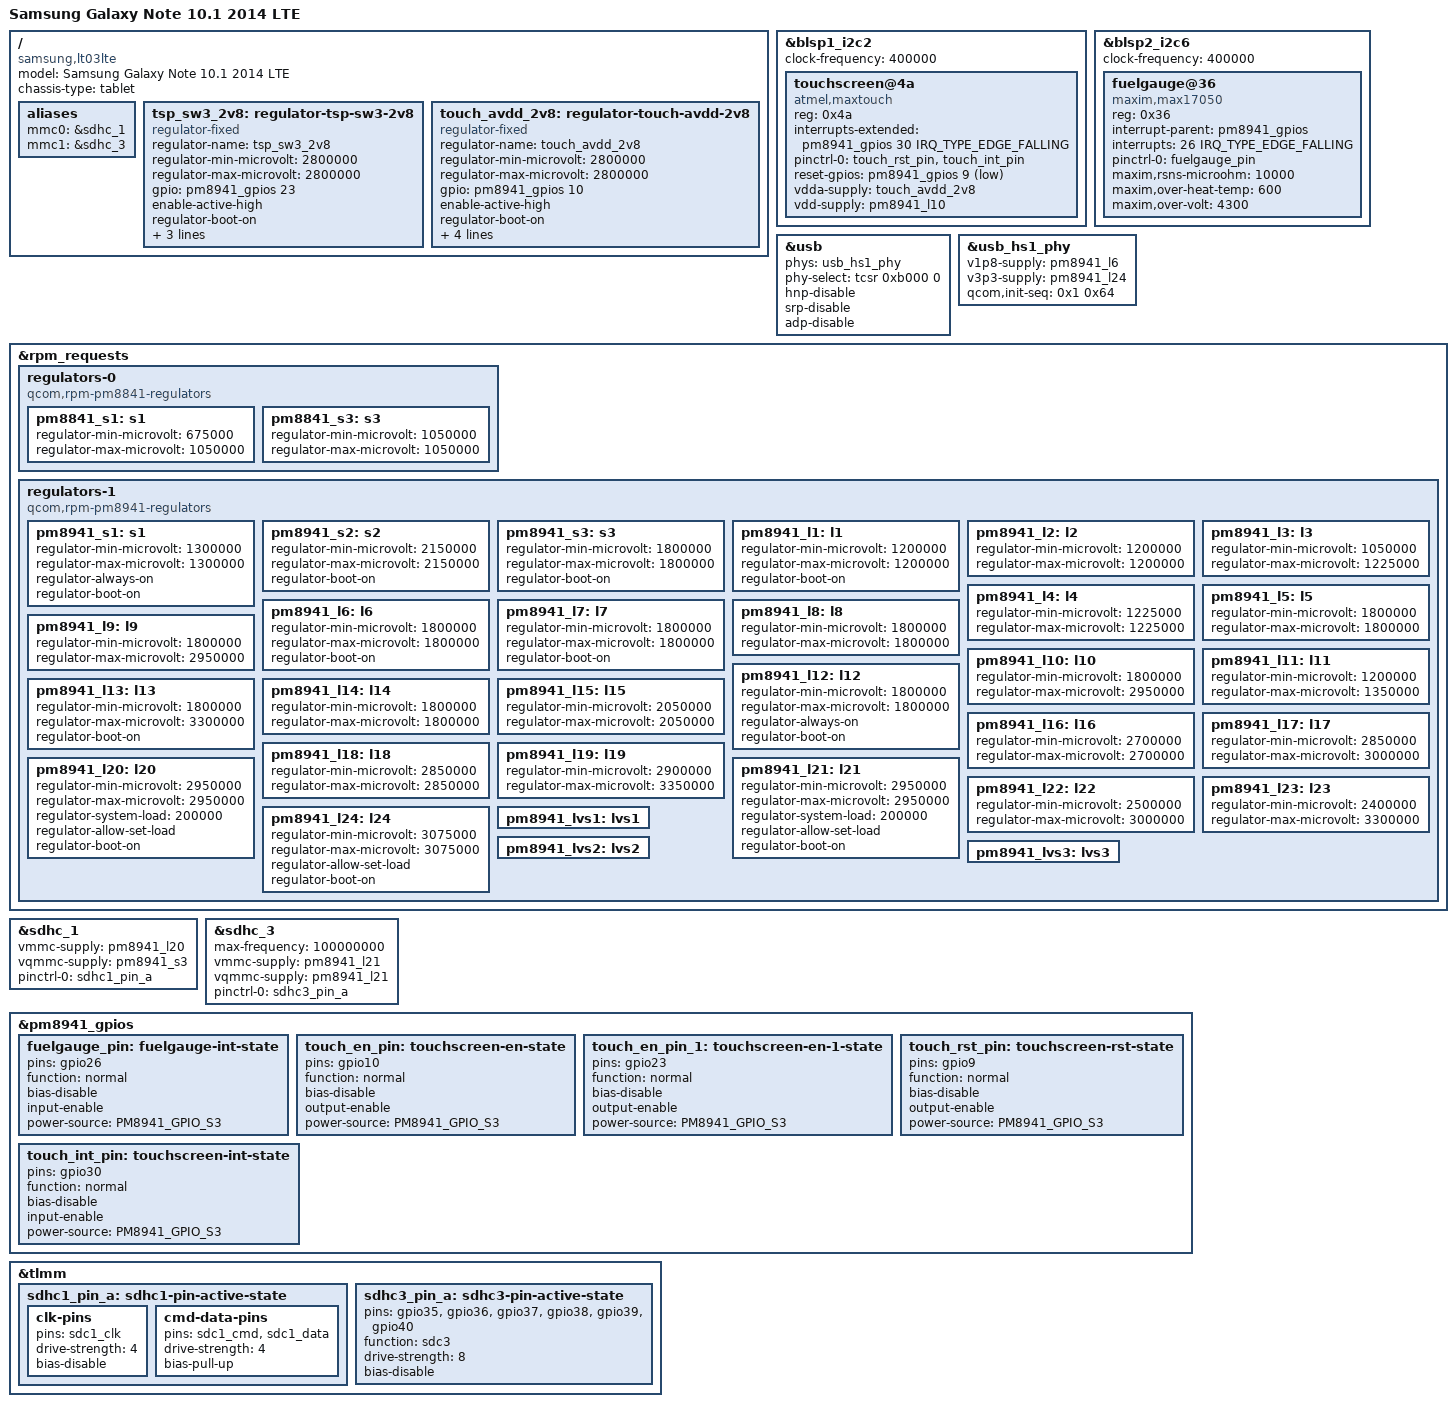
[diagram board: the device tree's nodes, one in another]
// SPDX-License-Identifier: GPL-2.0
#include "qcom-msm8974.dtsi"
#include "pm8841.dtsi"
#include "pm8941.dtsi"
#include <dt-bindings/pinctrl/qcom,pmic-gpio.h>

/ {
	model = "Samsung Galaxy Note 10.1 2014 LTE";
	compatible = "samsung,lt03lte", "qcom,msm8974";
	chassis-type = "tablet";

	aliases {
		mmc0 = &sdhc_1; /* SDC1 eMMC slot */
		mmc1 = &sdhc_3; /* SDC3 SD card slot */
	};

	tsp_sw3_2v8: regulator-tsp-sw3-2v8 {
		compatible = "regulator-fixed";
		regulator-name = "tsp_sw3_2v8";
		regulator-min-microvolt = <2800000>;
		regulator-max-microvolt = <2800000>;

		gpio = <&pm8941_gpios 23 GPIO_ACTIVE_HIGH>;
		enable-active-high;
		regulator-boot-on;

		startup-delay-us = <1000>;
		off-on-delay-us = <3000>;

		pinctrl-0 = <&touch_en_pin_1>;
		pinctrl-names = "default";
	};

	touch_avdd_2v8: regulator-touch-avdd-2v8 {
		compatible = "regulator-fixed";
		regulator-name = "touch_avdd_2v8";
		regulator-min-microvolt = <2800000>;
		regulator-max-microvolt = <2800000>;

		gpio = <&pm8941_gpios 10 GPIO_ACTIVE_HIGH>;
		enable-active-high;
		regulator-boot-on;

		startup-delay-us = <30000>;
		off-on-delay-us = <3000>;

		pinctrl-0 = <&touch_en_pin>;
		pinctrl-names = "default";

		vin-supply = <&tsp_sw3_2v8>; /* tsp_sw3_2v8 must be enabled first before AVDD */
	};
};

&blsp1_i2c2 {
	clock-frequency = <400000>;

	status = "okay";

	touchscreen@4a {
		compatible = "atmel,maxtouch";
		reg = <0x4a>;

		interrupts-extended = <&pm8941_gpios 30 IRQ_TYPE_EDGE_FALLING>;

		pinctrl-0 = <&touch_rst_pin &touch_int_pin>;
		pinctrl-names = "default";

		reset-gpios = <&pm8941_gpios 9 GPIO_ACTIVE_LOW>;
		vdda-supply = <&touch_avdd_2v8>;
		vdd-supply = <&pm8941_l10>;
	};
};

&blsp2_i2c6 {
	clock-frequency = <400000>;

	status = "okay";

	fuelgauge@36 {
		compatible = "maxim,max17050";
		reg = <0x36>;

		interrupt-parent = <&pm8941_gpios>;
		interrupts = <26 IRQ_TYPE_EDGE_FALLING>;

		pinctrl-0 = <&fuelgauge_pin>;
		pinctrl-names = "default";

		maxim,rsns-microohm = <10000>;
		maxim,over-heat-temp = <600>;
		maxim,over-volt = <4300>;
	};
};

&usb {
	phys = <&usb_hs1_phy>;
	phy-select = <&tcsr 0xb000 0>;

	hnp-disable;
	srp-disable;
	adp-disable;

	status = "okay";
};

&usb_hs1_phy {
	v1p8-supply = <&pm8941_l6>;
	v3p3-supply = <&pm8941_l24>;

	qcom,init-seq = /bits/ 8 <0x1 0x64>;

	status = "okay";
};

&rpm_requests {
	regulators-0 {
		compatible = "qcom,rpm-pm8841-regulators";

		pm8841_s1: s1 {
			regulator-min-microvolt = <675000>;
			regulator-max-microvolt = <1050000>;
		};

		pm8841_s3: s3 {
			regulator-min-microvolt = <1050000>;
			regulator-max-microvolt = <1050000>;
		};
	};

	regulators-1 {
		compatible = "qcom,rpm-pm8941-regulators";

		pm8941_s1: s1 {
			regulator-min-microvolt = <1300000>;
			regulator-max-microvolt = <1300000>;
			regulator-always-on;
			regulator-boot-on;
		};

		pm8941_s2: s2 {
			regulator-min-microvolt = <2150000>;
			regulator-max-microvolt = <2150000>;
			regulator-boot-on;
		};

		pm8941_s3: s3 {
			regulator-min-microvolt = <1800000>;
			regulator-max-microvolt = <1800000>;
			regulator-boot-on;
		};

		pm8941_l1: l1 {
			regulator-min-microvolt = <1200000>;
			regulator-max-microvolt = <1200000>;
			regulator-boot-on;
		};

		pm8941_l2: l2 {
			regulator-min-microvolt = <1200000>;
			regulator-max-microvolt = <1200000>;
		};

		pm8941_l3: l3 {
			regulator-min-microvolt = <1050000>;
			regulator-max-microvolt = <1225000>;
		};

		pm8941_l4: l4 {
			regulator-min-microvolt = <1225000>;
			regulator-max-microvolt = <1225000>;
		};

		pm8941_l5: l5 {
			regulator-min-microvolt = <1800000>;
			regulator-max-microvolt = <1800000>;
		};

		pm8941_l6: l6 {
			regulator-min-microvolt = <1800000>;
			regulator-max-microvolt = <1800000>;
			regulator-boot-on;
		};

		pm8941_l7: l7 {
			regulator-min-microvolt = <1800000>;
			regulator-max-microvolt = <1800000>;
			regulator-boot-on;
		};

		pm8941_l8: l8 {
			regulator-min-microvolt = <1800000>;
			regulator-max-microvolt = <1800000>;
		};

		pm8941_l9: l9 {
			regulator-min-microvolt = <1800000>;
			regulator-max-microvolt = <2950000>;
		};

		pm8941_l10: l10 {
			regulator-min-microvolt = <1800000>;
			regulator-max-microvolt = <2950000>;
		};

		pm8941_l11: l11 {
			regulator-min-microvolt = <1200000>;
			regulator-max-microvolt = <1350000>;
		};

		pm8941_l12: l12 {
			regulator-min-microvolt = <1800000>;
			regulator-max-microvolt = <1800000>;
			regulator-always-on;
			regulator-boot-on;
		};

		pm8941_l13: l13 {
			regulator-min-microvolt = <1800000>;
			regulator-max-microvolt = <3300000>;
			regulator-boot-on;
		};

		pm8941_l14: l14 {
			regulator-min-microvolt = <1800000>;
			regulator-max-microvolt = <1800000>;
		};

		pm8941_l15: l15 {
			regulator-min-microvolt = <2050000>;
			regulator-max-microvolt = <2050000>;
		};

		pm8941_l16: l16 {
			regulator-min-microvolt = <2700000>;
			regulator-max-microvolt = <2700000>;
		};

		pm8941_l17: l17 {
			regulator-min-microvolt = <2850000>;
			regulator-max-microvolt = <3000000>;
		};

		pm8941_l18: l18 {
			regulator-min-microvolt = <2850000>;
			regulator-max-microvolt = <2850000>;
		};

		pm8941_l19: l19 {
			regulator-min-microvolt = <2900000>;
			regulator-max-microvolt = <3350000>;
		};

		pm8941_l20: l20 {
			regulator-min-microvolt = <2950000>;
			regulator-max-microvolt = <2950000>;
			regulator-system-load = <200000>;
			regulator-allow-set-load;
			regulator-boot-on;
		};

		pm8941_l21: l21 {
			regulator-min-microvolt = <2950000>;
			regulator-max-microvolt = <2950000>;
			regulator-system-load = <200000>;
			regulator-allow-set-load;
			regulator-boot-on;
		};

		pm8941_l22: l22 {
			regulator-min-microvolt = <2500000>;
			regulator-max-microvolt = <3000000>;
		};

		pm8941_l23: l23 {
			regulator-min-microvolt = <2400000>;
			regulator-max-microvolt = <3300000>;
		};

		pm8941_l24: l24 {
			regulator-min-microvolt = <3075000>;
			regulator-max-microvolt = <3075000>;
			regulator-allow-set-load;
			regulator-boot-on;
		};

		pm8941_lvs1: lvs1 {};
		pm8941_lvs2: lvs2 {};
		pm8941_lvs3: lvs3 {};
	};
};

&sdhc_1 {
	vmmc-supply = <&pm8941_l20>;
	vqmmc-supply = <&pm8941_s3>;

	pinctrl-0 = <&sdhc1_pin_a>;
	pinctrl-names = "default";

	status = "okay";
};

&sdhc_3 {
	max-frequency = <100000000>;

	vmmc-supply = <&pm8941_l21>;
	vqmmc-supply = <&pm8941_l21>;

	pinctrl-0 = <&sdhc3_pin_a>;
	pinctrl-names = "default";

	status = "okay";
};

&pm8941_gpios {
	fuelgauge_pin: fuelgauge-int-state {
		pins = "gpio26";
		function = "normal";
		bias-disable;
		input-enable;
		power-source = <PM8941_GPIO_S3>;
	};

	touch_en_pin: touchscreen-en-state {
		pins = "gpio10";
		function = "normal";
		bias-disable;
		output-enable;
		power-source = <PM8941_GPIO_S3>;
	};

	touch_en_pin_1: touchscreen-en-1-state {
		pins = "gpio23";
		function = "normal";
		bias-disable;
		output-enable;
		power-source = <PM8941_GPIO_S3>;
	};

	touch_rst_pin: touchscreen-rst-state {
		pins = "gpio9";
		function = "normal";
		bias-disable;
		output-enable;
		power-source = <PM8941_GPIO_S3>;
	};

	touch_int_pin: touchscreen-int-state {
		pins = "gpio30";
		function = "normal";
		bias-disable;
		input-enable;
		power-source = <PM8941_GPIO_S3>;
	};
};

&tlmm {
	sdhc1_pin_a: sdhc1-pin-active-state {
		clk-pins {
			pins = "sdc1_clk";
			drive-strength = <4>;
			bias-disable;
		};

		cmd-data-pins {
			pins = "sdc1_cmd", "sdc1_data";
			drive-strength = <4>;
			bias-pull-up;
		};
	};

	sdhc3_pin_a: sdhc3-pin-active-state {
		pins = "gpio35", "gpio36", "gpio37", "gpio38", "gpio39", "gpio40";
		function = "sdc3";
		drive-strength = <8>;
		bias-disable;
	};
};
